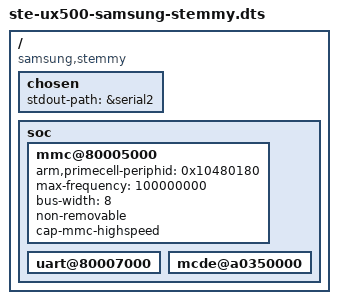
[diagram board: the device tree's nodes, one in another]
// SPDX-License-Identifier: GPL-2.0-or-later
/dts-v1/;

#include "ste-dbx5x0-u-boot.dtsi"
#include "ste-ab8500.dtsi"

/ {
	compatible = "samsung,stemmy", "st-ericsson,u8500";

	chosen {
		stdout-path = &serial2;
	};

	soc {
		/* eMMC */
		mmc@80005000 {
			status = "okay";

			arm,primecell-periphid = <0x10480180>;
			max-frequency = <100000000>;
			bus-width = <8>;

			non-removable;
			cap-mmc-highspeed;
		};

		/* Debugging console UART */
		uart@80007000 {
			status = "okay";
		};

		mcde@a0350000 {
			status = "okay";
		};
	};
};
